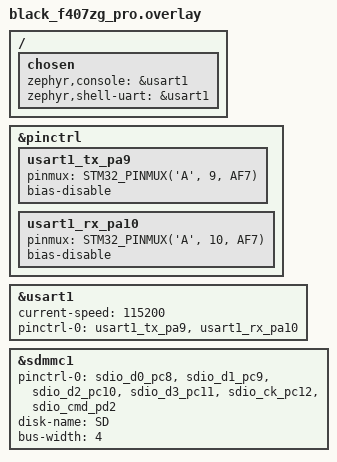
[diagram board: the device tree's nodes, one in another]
/*
 * Board overlay: route the Zephyr console to USART1 (PA9/PA10)
 * and enable 4-bit high-speed SDIO for the Micro-SD card slot.
 */

/ {
	chosen {
		zephyr,console = &usart1;
		zephyr,shell-uart = &usart1;
	};
};

&pinctrl {
	usart1_tx_pa9: usart1_tx_pa9 {
		pinmux = <STM32_PINMUX('A', 9, AF7)>;
		bias-disable;
	};

	usart1_rx_pa10: usart1_rx_pa10 {
		pinmux = <STM32_PINMUX('A', 10, AF7)>;
		bias-disable;
	};
};

&usart1 {
	status = "okay";
	current-speed = <115200>;
	pinctrl-0 = <&usart1_tx_pa9 &usart1_rx_pa10>;
	pinctrl-names = "default";
};

/* Enable 4-bit SDIO for the onboard Micro-SD / TF card socket */
&sdmmc1 {
	status = "okay";
	pinctrl-0 = <&sdio_d0_pc8 &sdio_d1_pc9 &sdio_d2_pc10 &sdio_d3_pc11 &sdio_ck_pc12 &sdio_cmd_pd2>;
	pinctrl-names = "default";
	disk-name = "SD";
	bus-width = <4>;
};
